# PIC16LF88 register map
Vendor: Microchip
Architecture 16xxxx. Special function registers and configuration words.
Registers are 8-bit, read-write, no defined reset value unless marked. A register's access mark holds for its fields unless they carry their own. Addresses are absolute, and some are shared; only a register's first bit layout is shown; lines under a group give offsets from that group; [hi:lo] are bit positions; {n}, {i} and the like mark numbered series; 'fields as' and 'values as' point back to an identical list; <NAME> marks a mode.

## Further device data
pins=1: RA2/AN2/CVref/Vref-; 2: RA3/AN3/Vref+/C1OUT; 3: RA4/AN4/T0CKI/C2OUT; 4: RA5/MCLR/Vpp; 5: Vss; 6: RB0/INT/CCP1; 7: RB1/SDI/SDA; 8: RB2/SDO/RX/DT; 9: RB3/PGM/CCP1; 10: RB4/SCK/SCL; 11: RB5/SS/TX/CK; 12: RB6/AN5/PGC/T1OSO/T1CKI; 13: RB7/AN6/PGD/T1OSI; 14: Vdd; 15: RA6/OSC2/CLKO; 16: RA7/OSC1/CLKI; 17: RA0/AN0; 18: RA1/AN1

## SFR
0x00 INDF access not given
0x01 TMR0 — (power-on value xxxxxxxx)
0x02 PCL reset 0x0
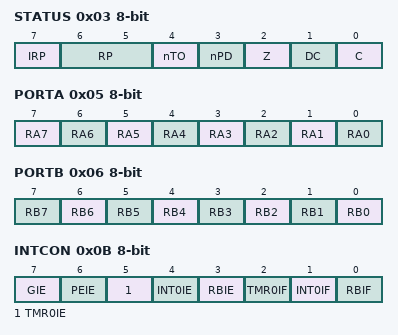
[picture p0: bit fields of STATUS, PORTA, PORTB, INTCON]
0x03 STATUS — (power-on value 00011xxx)
  [7] IRP, [6:5] RP, [4] nTO ro, [3] nPD ro, [2] Z, [1] DC, [0] C
0x04 FSR — (power-on value xxxxxxxx)
0x05 PORTA — (power-on value xxx00000)
  [7] RA7, [6] RA6, [5] RA5 ro, [n] RA{n} (n=0..4)
0x06 PORTB — (power-on value 00xxxxxx)
  [n] RB{n} (n=0..7)
0x0A PCLATH reset 0x0
  [4:0] PCLATH
0x0B INTCON — (power-on value 0000000x)
  [7] GIE, [6] PEIE, [5] TMR0IE, [4] INT0IE, [3] RBIE, [2] TMR0IF, [1] INT0IF, [0] RBIF
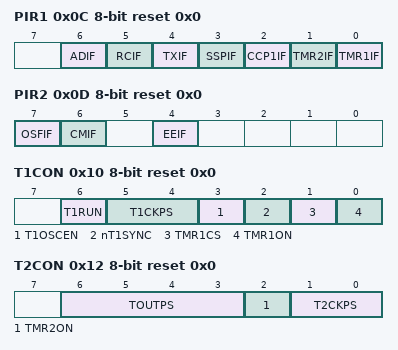
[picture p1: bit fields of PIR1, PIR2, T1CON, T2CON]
0x0C PIR1 reset 0x0
  [6] ADIF, [5] RCIF ro, [4] TXIF ro, [3] SSPIF ro, [2] CCP1IF, [1] TMR2IF, [0] TMR1IF
0x0D PIR2 reset 0x0
  [7] OSFIF, [6] CMIF, [4] EEIF
0x0E TMR1L — (power-on value xxxxxxxx)
0x0F TMR1H — (power-on value xxxxxxxx)
0x10 T1CON reset 0x0
  [6] T1RUN ro, [5:4] T1CKPS, [3] T1OSCEN, [2] nT1SYNC, [1] TMR1CS, [0] TMR1ON
0x11 TMR2 reset 0x0
0x12 T2CON reset 0x0
  [6:3] TOUTPS, [2] TMR2ON, [1:0] T2CKPS
0x13 SSPBUF — (power-on value xxxxxxxx)
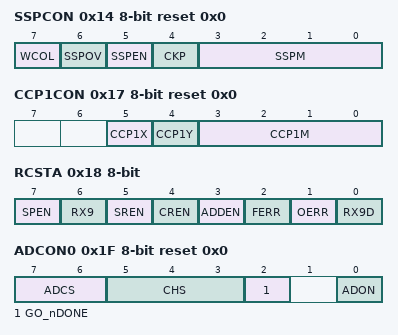
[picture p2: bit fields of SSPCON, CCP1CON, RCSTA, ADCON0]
0x14 SSPCON reset 0x0
  [7] WCOL, [6] SSPOV, [5] SSPEN, [4] CKP, [3:0] SSPM
0x15 CCPR1L — (power-on value xxxxxxxx)
0x16 CCPR1H — (power-on value xxxxxxxx)
0x17 CCP1CON reset 0x0
  [5] CCP1X, [4] CCP1Y, [3:0] CCP1M
0x18 RCSTA — (power-on value 0000000x)
  [7] SPEN, [6] RX9, [5] SREN, [4] CREN, [3] ADDEN, [2] FERR ro, [1] OERR ro, [0] RX9D ro
0x19 TXREG reset 0x0
0x1A RCREG ro reset 0x0
0x1E ADRESH — (power-on value xxxxxxxx)
0x1F ADCON0 reset 0x0
  [7:6] ADCS, [5:3] CHS, [2] GO_nDONE, [0] ADON
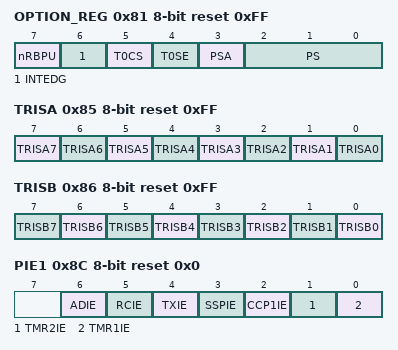
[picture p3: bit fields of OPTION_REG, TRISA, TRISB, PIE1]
0x81 OPTION_REG reset 0xFF
  [7] nRBPU, [6] INTEDG, [5] T0CS, [4] T0SE, [3] PSA, [2:0] PS
0x85 TRISA reset 0xFF
  [7] TRISA7, [6] TRISA6, [5] TRISA5 ro, [n] TRISA{n} (n=0..4)
0x86 TRISB reset 0xFF
  [n] TRISB{n} (n=0..7)
0x8C PIE1 reset 0x0
  [6] ADIE, [5] RCIE, [4] TXIE, [3] SSPIE, [2] CCP1IE, [1] TMR2IE, [0] TMR1IE
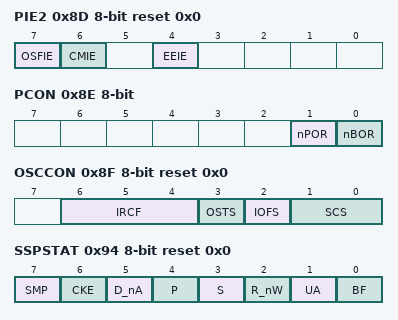
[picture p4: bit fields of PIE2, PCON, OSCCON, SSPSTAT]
0x8D PIE2 reset 0x0
  [7] OSFIE, [6] CMIE, [4] EEIE
0x8E PCON — (power-on value ------qq)
  [1] nPOR, [0] nBOR
0x8F OSCCON reset 0x0
  [6:4] IRCF, [3] OSTS ro, [2] IOFS, [1:0] SCS
0x90 OSCTUNE reset 0x0
  [5:0] TUN
0x92 PR2 reset 0xFF
0x93 SSPADD reset 0x0
0x94 SSPSTAT reset 0x0
  [7] SMP, [6] CKE, [5] D_nA, [4] P, [3] S, [2] R_nW, [1] UA, [0] BF
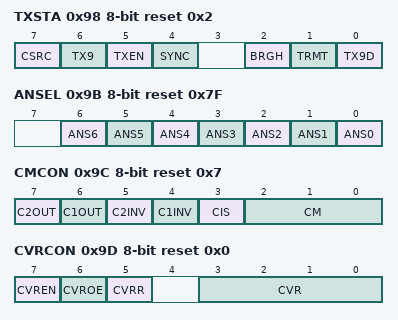
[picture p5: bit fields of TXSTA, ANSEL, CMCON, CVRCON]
0x98 TXSTA reset 0x2
  [7] CSRC, [6] TX9, [5] TXEN, [4] SYNC, [2] BRGH, [1] TRMT ro, [0] TX9D
0x99 SPBRG reset 0x0
0x9B ANSEL reset 0x7F
  [n] ANS{n} (n=0..6)
0x9C CMCON reset 0x7
  [7] C2OUT ro, [6] C1OUT ro, [5] C2INV, [4] C1INV, [3] CIS, [2:0] CM
0x9D CVRCON reset 0x0
  [7] CVREN, [6] CVROE, [5] CVRR, [3:0] CVR
0x9E ADRESL — (power-on value xxxxxxxx)
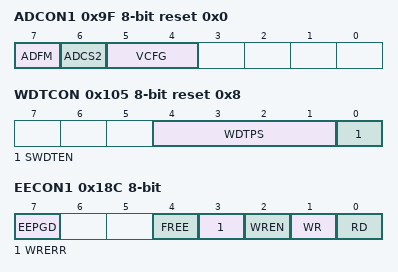
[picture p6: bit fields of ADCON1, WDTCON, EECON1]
0x9F ADCON1 reset 0x0
  [7] ADFM, [6] ADCS2, [5:4] VCFG
0x105 WDTCON reset 0x8
  [4:1] WDTPS, [0] SWDTEN
0x10C EEDATA — (power-on value xxxxxxxx)
0x10D EEADR — (power-on value xxxxxxxx)
0x10E EEDATH — (power-on value --xxxxxx)
  [5:0] EEDATH
0x10F EEADRH — (power-on value ----xxxx)
  [3:0] EEADRH
0x18C EECON1 — (power-on value x--xx000)
  [7] EEPGD
  [4] FREE
  [3] WRERR
  [2] WREN
  [1] WR — (can only be set)
  [0] RD — (can only be set)
0x18D EECON2 wo

## CONFIG — Configuration words, addresses in ProgramSpace
0x2007 CONFIG1 14-bit reset 0x3FFF
  [13] CP — Flash Program Memory Code Protection bit
    1=OFF (Code protection off); 0=ON (0000h to 0FFFh code-protected (all protected))
  [12] CCPMX — CCP1 Pin Selection bit
    1=RB0 (CCP1 function on RB0); 0=RB3 (CCP1 function on RB3)
  [11] DEBUG — In-Circuit Debugger Mode bit
    1=OFF (In-Circuit Debugger disabled, RB6 and RB7 are general purpose I/O pins); 0=ON (In-Circuit Debugger enabled, RB6 and RB7 are dedicated to the debugger)
  [10:9] WRT — Flash Program Memory Write Enable bits
    3=OFF (Write protection off); 2=0000h to 00FFh write-protected, 0100h to 0FFFh may be modified by EECON control; 1=0000h to 07FFh write-protected, 0800h to 0FFFh may be modified by EECON control; 0=ALL (0000h to 0FFFh write-protected)
  [8] CPD — Data EE Memory Code Protection bit
    1=OFF (Code protection off); 0=ON (Data EE memory code-protected)
  [7] LVP — Low-Voltage Programming Enable bit
    1=ON (RB3/PGM pin has PGM function, Low-Voltage Programming enabled); 0=OFF (RB3 is digital I/O, HV on MCLR must be used for programming)
  [6] BOREN — Brown-out Reset Enable bit
    1=ON (BOR enabled); 0=OFF (BOR disabled)
  [5] MCLRE — RA5/MCLR/VPP Pin Function Select bit
    1=ON (RA5/MCLR/VPP pin function is MCLR); 0=OFF (RA5/MCLR/VPP pin function is digital I/O, MCLR internally tied to VDD)
  [3] PWRTE — Power-up Timer Enable bit
    1=OFF (PWRT disabled); 0=ON (PWRT enabled)
  [2] WDTE — Watchdog Timer Enable bit
    1=ON (WDT enabled); 0=OFF (WDT disabled)
  [4:0] FOSC — Oscillator Selection bits
    0b1xx11=EXTRCCLK (EXTRC oscillator; CLKO function on RA6/OSC2/CLKO); 0b1xx10=EXTRCIO (EXTRC oscillator; port I/O function on RA6/OSC2/CLKO); 0b1xx01=INTOSCCLK (INTRC oscillator; CLKO function on RA6/OSC2/CLKO pin and port I/O function on RA7/OSC1/CLKI pin); 0b1xx00=INTOSCIO (INTRC oscillator; port I/O function on both RA6/OSC2/CLKO pin and RA7/OSC1/CLKI pin); 0b0xx11=EC (ECIO; port I/O function on RA6/OSC2/CLKO); 0b0xx10=HS (HS oscillator); 0b0xx01=XT (XT oscillator); 0b0xx00=LP (LP oscillator)
0x2008 CONFIG2 14-bit reset 0x3FFF
  [1] IESO — Internal External Switchover bit
    1=ON (Internal External Switchover mode enabled); 0=OFF (Internal External Switchover mode disabled)
  [0] FCMEN — Fail-Safe Clock Monitor Enable bit
    1=ON (Fail-Safe Clock Monitor enabled); 0=OFF (Fail-Safe Clock Monitor disabled)
